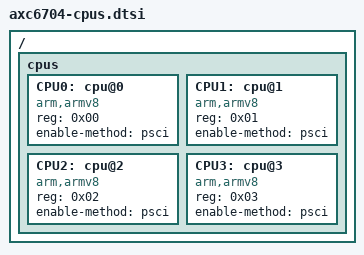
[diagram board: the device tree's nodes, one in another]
// SPDX-License-Identifier: GPL-2.0
// Copyright (C) 2021 INTEL Corporation

/ {
	cpus {
		#address-cells = <1>;
		#size-cells = <0>;

		CPU0: cpu@0 {
			device_type = "cpu";
			compatible = "arm,armv8";
			reg = <0x00>;
			enable-method = "psci";
		};

		CPU1: cpu@1 {
			device_type = "cpu";
			compatible = "arm,armv8";
			reg = <0x01>;
			enable-method = "psci";
		};

		CPU2: cpu@2 {
			device_type = "cpu";
			compatible = "arm,armv8";
			reg = <0x02>;
			enable-method = "psci";
		};

		CPU3: cpu@3 {
			device_type = "cpu";
			compatible = "arm,armv8";
			reg = <0x03>;
			enable-method = "psci";
		};
	};
};
